CM_ "IMPORT _comma.dbc";
CM_ "IMPORT _honda_common.dbc";
CM_ "IMPORT _bosch_2018.dbc";
CM_ "IMPORT _steering_sensors_a.dbc";

BO_ 304 GAS_PEDAL_2: 8 PCM
 SG_ 6MT_SHIFTER : 49|2@0+ (1,0) [0|3] "" XXX
 SG_ CLUTCH_PEDAL : 51|2@0+ (1,0) [0|3] "" XXX

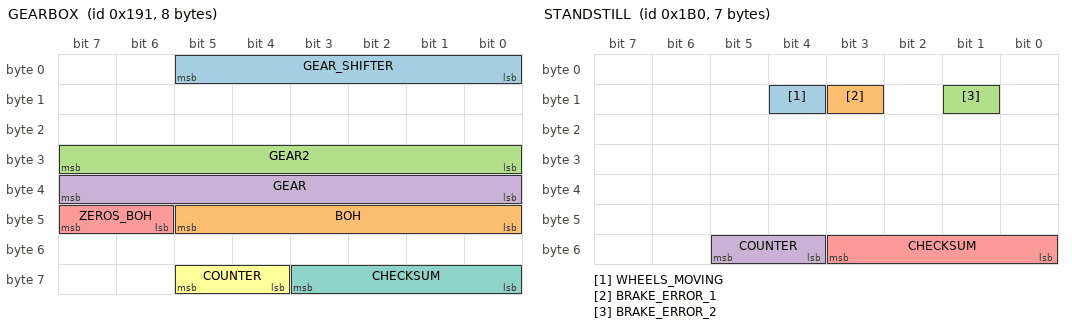
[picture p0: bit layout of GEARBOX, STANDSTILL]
BO_ 401 GEARBOX: 8 PCM
 SG_ GEAR_SHIFTER : 5|6@0+ (1,0) [0|63] "" EON
 SG_ BOH : 45|6@0+ (1,0) [0|63] "" XXX
 SG_ GEAR2 : 31|8@0+ (1,0) [0|1] "" XXX
 SG_ GEAR : 39|8@0+ (1,0) [0|255] "" XXX
 SG_ ZEROS_BOH : 47|2@0+ (1,0) [0|3] "" XXX
 SG_ COUNTER : 61|2@0+ (1,0) [0|3] "" EON
 SG_ CHECKSUM : 59|4@0+ (1,0) [0|15] "" EON

BO_ 432 STANDSTILL: 7 VSA
 SG_ WHEELS_MOVING : 12|1@0+ (1,0) [0|1] "" EON
 SG_ BRAKE_ERROR_1 : 11|1@0+ (1,0) [0|1] "" EON
 SG_ BRAKE_ERROR_2 : 9|1@0+ (1,0) [0|1] "" EON
 SG_ COUNTER : 53|2@0+ (1,0) [0|3] "" EON
 SG_ CHECKSUM : 51|4@0+ (1,0) [0|15] "" EON

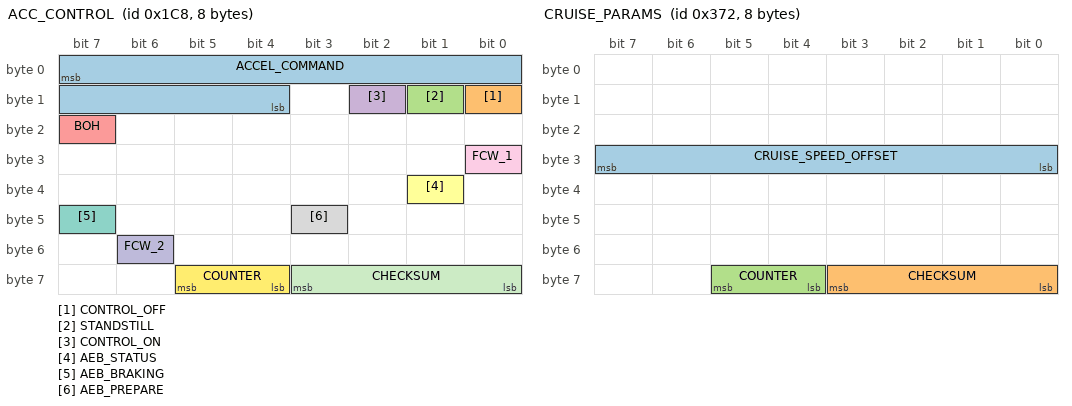
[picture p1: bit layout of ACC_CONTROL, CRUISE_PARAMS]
BO_ 456 ACC_CONTROL: 8 XXX
 SG_ ACCEL_COMMAND : 7|12@0- (0.01,0) [0|0] "m/s^2" XXX
 SG_ CONTROL_OFF : 8|1@0+ (1,0) [0|1] "" XXX
 SG_ STANDSTILL : 9|1@0+ (1,0) [0|1] "" XXX
 SG_ CONTROL_ON : 10|1@0+ (1,0) [0|1] "" XXX
 SG_ BOH : 23|1@0+ (1,0) [0|1] "" XXX
 SG_ AEB_STATUS : 33|1@1+ (1,0) [0|7] "" XXX
 SG_ AEB_BRAKING : 47|1@0+ (1,0) [0|1] "" XXX
 SG_ AEB_PREPARE : 43|1@0+ (1,0) [0|1] "" XXX
 SG_ FCW_1 : 24|1@1+ (1,0) [0|3] "" XXX
 SG_ FCW_2 : 54|1@0+ (1,0) [0|3] "" XXX
 SG_ CHECKSUM : 59|4@0+ (1,0) [0|15] "" XXX
 SG_ COUNTER : 61|2@0+ (1,0) [0|3] "" XXX

BO_ 477 6MT_GEAR: 8 XXX
 SG_ 6MT_GEARBOX : 39|4@0+ (1,0) [0|15] "" XXX

BO_ 829 LKAS_HUD: 8 ADAS
 SG_ CAM_TEMP_HIGH : 7|1@0+ (1,0) [0|255] "" BDY
 SG_ SET_ME_X41 : 6|7@0+ (1,0) [0|127] "" BDY
 SG_ BOH : 6|7@0+ (1,0) [0|127] "" BDY
 SG_ DASHED_LANES : 14|1@0+ (1,0) [0|1] "" BDY
 SG_ DTC : 13|1@0+ (1,0) [0|1] "" BDY
 SG_ LKAS_PROBLEM : 12|1@0+ (1,0) [0|1] "" BDY
 SG_ LKAS_OFF : 11|1@0+ (1,0) [0|1] "" BDY
 SG_ SOLID_LANES : 10|1@0+ (1,0) [0|1] "" BDY
 SG_ LDW_RIGHT : 9|1@0+ (1,0) [0|1] "" BDY
 SG_ STEERING_REQUIRED : 8|1@0+ (1,0) [0|1] "" BDY
 SG_ BOH : 23|2@0+ (1,0) [0|4] "" BDY
 SG_ LDW_PROBLEM : 21|1@0+ (1,0) [0|1] "" BDY
 SG_ BEEP : 17|2@0+ (1,0) [0|1] "" BDY
 SG_ LDW_ON : 28|1@0+ (1,0) [0|1] "" BDY
 SG_ LDW_OFF : 27|1@0+ (1,0) [0|1] "" BDY
 SG_ CLEAN_WINDSHIELD : 26|1@0+ (1,0) [0|1] "" BDY
 SG_ SET_ME_X48 : 31|8@0+ (1,0) [0|255] "" BDY
 SG_ LANE_LINES : 36|2@0+ (1,0) [0|3] "" BDY
 SG_ COUNTER : 61|2@0+ (1,0) [0|3] "" BDY
 SG_ CHECKSUM : 59|4@0+ (1,0) [0|15] "" BDY

BO_ 882 CRUISE_PARAMS: 8 PCM
 SG_ CRUISE_SPEED_OFFSET : 31|8@0- (0.1,0) [-128|127] "kph" EON
 SG_ CHECKSUM : 59|4@0+ (1,0) [0|3] "" EON
 SG_ COUNTER : 61|2@0+ (1,0) [0|15] "" EON

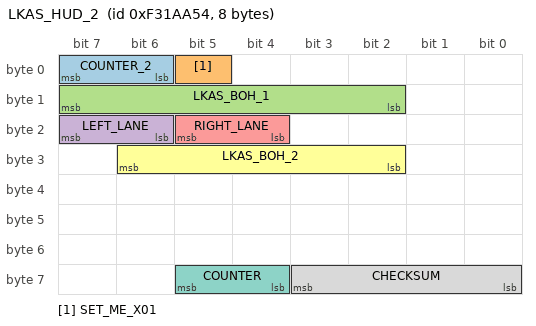
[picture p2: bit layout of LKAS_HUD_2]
BO_ 254913108 LKAS_HUD_2: 8 ADAS
 SG_ COUNTER_2 : 7|2@0+ (1,0) [0|3] "" XXX
 SG_ SET_ME_X01 : 5|1@0+ (1,0) [0|1] "" XXX
 SG_ LKAS_BOH_1 : 15|6@0+ (1,0) [0|63] "" XXX
 SG_ LEFT_LANE : 23|2@0+ (1,0) [0|3] "" XXX
 SG_ RIGHT_LANE : 21|2@0+ (1,0) [0|3] "" XXX
 SG_ LKAS_BOH_2 : 30|5@0+ (1,0) [0|31] "" XXX
 SG_ COUNTER : 61|2@0+ (1,0) [0|3] "" XXX
 SG_ CHECKSUM : 59|4@0+ (1,0) [0|15] "" XXX

CM_ SG_ 304 6MT_SHIFTER "Gears 1-6 are D";
CM_ SG_ 304 CLUTCH_PEDAL "The clutch pedal has three valid states: Partial (slipping), released (engaged), and fully depressed (disengaged)";
CM_ BO_ 456 "not sure which bit enables cruise";
CM_ SG_ 456 STANDSTILL "set to 1 when camera requests -4.0 m/s^2";
CM_ SG_ 477 6MT_GEARBOX "Values are only >0 if clutch is released. 1 is both 1st gear and Neutral. Use 6MT_SHIFTER to confirm 1st or N";

VAL_ 304 6MT_SHIFTER 0 "D" 1 "N" 2 "R" ;
VAL_ 304 CLUTCH_PEDAL 0 "Slipping" 1 "Released" 2 "Depressed" ;
VAL_ 401 GEAR_SHIFTER 32 "L" 16 "S" 8 "D" 4 "N" 2 "R" 1 "P";
VAL_ 401 GEAR 7 "L" 10 "S" 4 "D" 3 "N" 2 "R" 1 "P";
VAL_ 477 6MT_GEARBOX 0 "Clutch" 1 "1" 2 "2" 3 "3" 4 "4" 5 "5" 6 "6" 14 "R";
